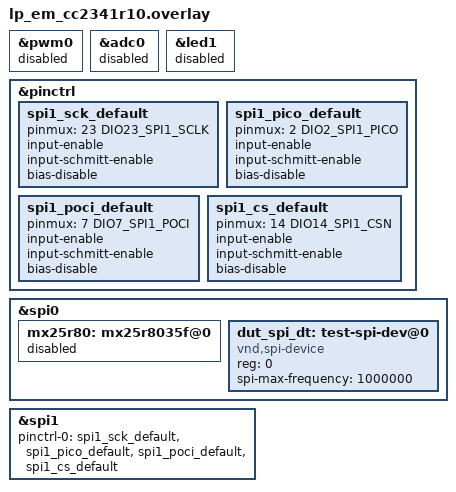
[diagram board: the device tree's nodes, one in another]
/*
 * Copyright (c) 2026 Texas Instruments Incorporated
 *
 * SPDX-License-Identifier: Apache-2.0
 */

&pwm0 {
	status = "disabled";
};

&adc0 {
	status = "disabled";
};

&led1 {
	status = "disabled";
};

&pinctrl {
	spi1_sck_default: spi1_sck_default {
		pinmux = <23 DIO23_SPI1_SCLK>;
		input-enable;
		input-schmitt-enable;
		bias-disable;
	};

	spi1_pico_default: spi1_pico_default {
		pinmux = <2 DIO2_SPI1_PICO>;
		input-enable;
		input-schmitt-enable;
		bias-disable;
	};

	spi1_poci_default: spi1_poci_default {
		pinmux = <7 DIO7_SPI1_POCI>;
		input-enable;
		input-schmitt-enable;
		bias-disable;
	};

	spi1_cs_default: spi1_cs_default {
		pinmux = <14 DIO14_SPI1_CSN>;
		input-enable;
		input-schmitt-enable;
		bias-disable;
	};
};

&spi0 {
	/delete-property/ cs-gpios;

	mx25r80: mx25r8035f@0 {
		status = "disabled";
	};

	dut_spi_dt: test-spi-dev@0 {
		compatible = "vnd,spi-device";
		reg = <0>;
		spi-max-frequency = <1000000>;
	};
};

dut_spis: &spi1 {
	status = "okay";
	pinctrl-0 = <&spi1_sck_default
		     &spi1_pico_default
		     &spi1_poci_default
		     &spi1_cs_default>;
	pinctrl-names = "default";
};
